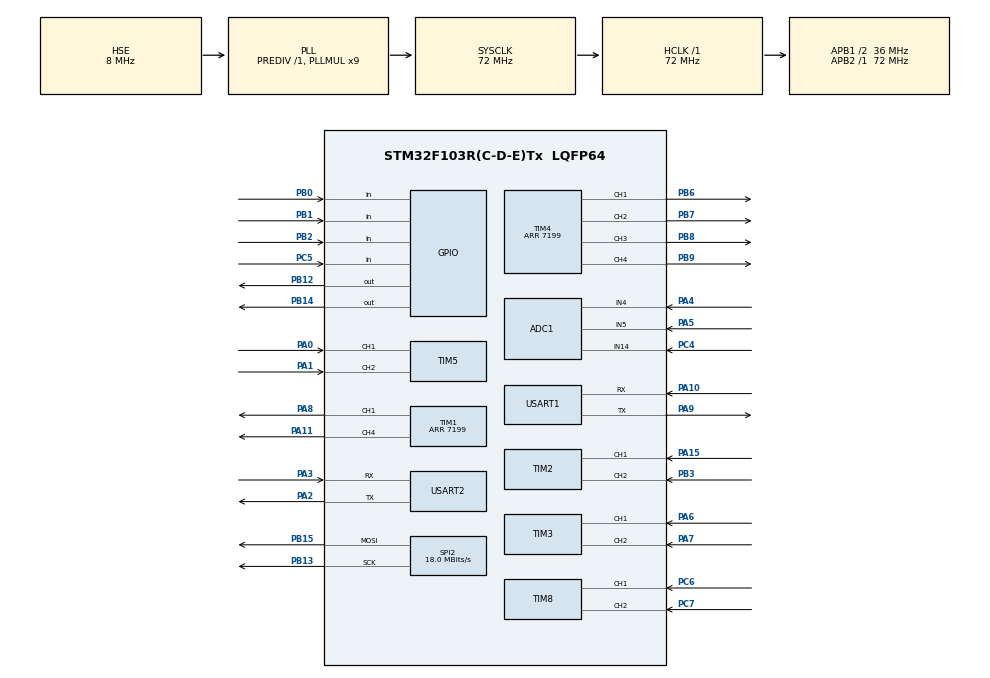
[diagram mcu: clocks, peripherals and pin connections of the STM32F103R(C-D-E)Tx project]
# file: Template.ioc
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ADC1.Channel-0\#ChannelRegularConversion=ADC_CHANNEL_4
ADC1.Channel-1\#ChannelRegularConversion=ADC_CHANNEL_5
ADC1.Channel-2\#ChannelRegularConversion=ADC_CHANNEL_14
ADC1.NbrOfConversion=3
ADC1.NbrOfConversionFlag=1
ADC1.Rank-0\#ChannelRegularConversion=1
ADC1.Rank-1\#ChannelRegularConversion=2
ADC1.Rank-2\#ChannelRegularConversion=3
ADC1.SamplingTime-0\#ChannelRegularConversion=ADC_SAMPLETIME_71CYCLES_5
ADC1.SamplingTime-1\#ChannelRegularConversion=ADC_SAMPLETIME_71CYCLES_5
ADC1.SamplingTime-2\#ChannelRegularConversion=ADC_SAMPLETIME_71CYCLES_5
ADC1.master=1
Dma.ADC1.3.Direction=DMA_PERIPH_TO_MEMORY
Dma.ADC1.3.Instance=DMA1_Channel1
Dma.ADC1.3.MemDataAlignment=DMA_MDATAALIGN_HALFWORD
Dma.ADC1.3.MemInc=DMA_MINC_ENABLE
Dma.ADC1.3.Mode=DMA_NORMAL
Dma.ADC1.3.PeriphDataAlignment=DMA_PDATAALIGN_HALFWORD
Dma.ADC1.3.PeriphInc=DMA_PINC_DISABLE
Dma.ADC1.3.Priority=DMA_PRIORITY_MEDIUM
Dma.Request0=USART2_RX
Dma.Request1=USART2_TX
Dma.Request2=SPI2_TX
Dma.Request3=ADC1
Dma.SPI2_TX.2.Direction=DMA_MEMORY_TO_PERIPH
Dma.SPI2_TX.2.Instance=DMA1_Channel5
Dma.SPI2_TX.2.MemDataAlignment=DMA_MDATAALIGN_BYTE
Dma.SPI2_TX.2.MemInc=DMA_MINC_ENABLE
Dma.SPI2_TX.2.Mode=DMA_NORMAL
Dma.SPI2_TX.2.PeriphDataAlignment=DMA_PDATAALIGN_BYTE
Dma.SPI2_TX.2.PeriphInc=DMA_PINC_DISABLE
Dma.SPI2_TX.2.Priority=DMA_PRIORITY_HIGH
Dma.USART2_RX.0.Direction=DMA_PERIPH_TO_MEMORY
Dma.USART2_RX.0.Instance=DMA1_Channel6
Dma.USART2_RX.0.MemDataAlignment=DMA_MDATAALIGN_BYTE
Dma.USART2_RX.0.MemInc=DMA_MINC_ENABLE
Dma.USART2_RX.0.Mode=DMA_CIRCULAR
Dma.USART2_RX.0.PeriphDataAlignment=DMA_PDATAALIGN_BYTE
Dma.USART2_RX.0.PeriphInc=DMA_PINC_DISABLE
Dma.USART2_RX.0.Priority=DMA_PRIORITY_LOW
Dma.USART2_TX.1.Direction=DMA_MEMORY_TO_PERIPH
Dma.USART2_TX.1.Instance=DMA1_Channel7
Dma.USART2_TX.1.MemDataAlignment=DMA_MDATAALIGN_BYTE
Dma.USART2_TX.1.MemInc=DMA_MINC_ENABLE
Dma.USART2_TX.1.Mode=DMA_NORMAL
Dma.USART2_TX.1.PeriphDataAlignment=DMA_PDATAALIGN_BYTE
Dma.USART2_TX.1.PeriphInc=DMA_PINC_DISABLE
Dma.USART2_TX.1.Priority=DMA_PRIORITY_LOW
Mcu.Family=STM32F1
Mcu.Name=STM32F103R(C-D-E)Tx
Mcu.Package=LQFP64
NVIC.DMA1_Channel1_IRQn=true\:5\:0\:true\:false\:true\:false\:true\:true
NVIC.DMA1_Channel5_IRQn=true\:5\:0\:true\:false\:true\:false\:true\:true
NVIC.DMA1_Channel6_IRQn=true\:5\:0\:true\:false\:true\:false\:true\:true
NVIC.DMA1_Channel7_IRQn=true\:5\:0\:true\:false\:true\:false\:true\:true
NVIC.PriorityGroup=NVIC_PRIORITYGROUP_4
NVIC.SPI2_IRQn=true\:7\:0\:true\:false\:true\:true\:true\:true
NVIC.TIM7_IRQn=true\:10\:0\:true\:false\:true\:true\:true\:true
NVIC.USART2_IRQn=true\:6\:0\:true\:false\:true\:true\:true\:true
PA0-WKUP.Signal=S_TIM5_CH1
PA1.Signal=S_TIM5_CH2
PA10.Mode=Asynchronous
PA10.Signal=USART1_RX
PA11.Signal=S_TIM1_CH4
PA13.Mode=Serial_Wire
PA13.Signal=SYS_JTMS-SWDIO
PA14.Mode=Serial_Wire
PA14.Signal=SYS_JTCK-SWCLK
PA15.Signal=S_TIM2_CH1_ETR
PA2.Mode=Asynchronous
PA2.Signal=USART2_TX
PA3.GPIO_PuPd=GPIO_PULLUP
PA3.Mode=Asynchronous
PA3.Signal=USART2_RX
PA4.Signal=ADCx_IN4
PA5.Signal=ADCx_IN5
PA6.Signal=S_TIM3_CH1
PA7.Signal=S_TIM3_CH2
PA8.Signal=S_TIM1_CH1
PA9.Mode=Asynchronous
PA9.Signal=USART1_TX
PB0.GPIO_PuPd=GPIO_PULLUP
PB0.Signal=GPIO_Input
PB1.GPIO_PuPd=GPIO_PULLUP
PB1.Signal=GPIO_Input
PB12.Signal=GPIO_Output
PB13.Mode=TX_Only_Simplex_Unidirect_Master
PB13.Signal=SPI2_SCK
PB14.Signal=GPIO_Output
PB15.Mode=TX_Only_Simplex_Unidirect_Master
PB15.Signal=SPI2_MOSI
PB2.GPIO_PuPd=GPIO_PULLUP
PB2.Signal=GPIO_Input
PB3.Signal=S_TIM2_CH2
PB6.Signal=S_TIM4_CH1
PB7.Signal=S_TIM4_CH2
PB8.Signal=S_TIM4_CH3
PB9.Signal=S_TIM4_CH4
PC4.Signal=ADCx_IN14
PC5.GPIO_PuPd=GPIO_PULLUP
PC5.Signal=GPIO_Input
PC6.Signal=S_TIM8_CH1
PC7.Signal=S_TIM8_CH2
PD0-OSC_IN.Mode=HSE-External-Oscillator
PD0-OSC_IN.Signal=RCC_OSC_IN
PD1-OSC_OUT.Mode=HSE-External-Oscillator
PD1-OSC_OUT.Signal=RCC_OSC_OUT
ProjectManager.HeapSize=0x200
ProjectManager.StackSize=0x400
ProjectManager.TargetToolchain=MDK-ARM V5.32
RCC.ADCPresc=RCC_ADCPCLK2_DIV6
RCC.AHBFreq_Value=72000000
RCC.APB1CLKDivider=RCC_HCLK_DIV2
RCC.APB1Freq_Value=36000000
RCC.APB1TimFreq_Value=72000000
RCC.APB2Freq_Value=72000000
RCC.APB2TimFreq_Value=72000000
RCC.HCLKFreq_Value=72000000
RCC.PLLMUL=RCC_PLL_MUL9
RCC.PLLSourceVirtual=RCC_PLLSOURCE_HSE
RCC.SYSCLKFreq_VALUE=72000000
RCC.SYSCLKSource=RCC_SYSCLKSOURCE_PLLCLK
RCC.USBFreq_Value=72000000
SH.ADCx_IN14.0=ADC1_IN14,IN14
SH.ADCx_IN4.0=ADC1_IN4,IN4
SH.ADCx_IN5.0=ADC1_IN5,IN5
SH.S_TIM1_CH1.0=TIM1_CH1,PWM Generation1 CH1
SH.S_TIM1_CH4.0=TIM1_CH4,PWM Generation4 CH4
SH.S_TIM2_CH1_ETR.0=TIM2_CH1,Encoder_Interface
SH.S_TIM2_CH2.0=TIM2_CH2,Encoder_Interface
SH.S_TIM3_CH1.0=TIM3_CH1,Encoder_Interface
SH.S_TIM3_CH2.0=TIM3_CH2,Encoder_Interface
SH.S_TIM4_CH1.0=TIM4_CH1,PWM Generation1 CH1
SH.S_TIM4_CH2.0=TIM4_CH2,PWM Generation2 CH2
SH.S_TIM4_CH3.0=TIM4_CH3,PWM Generation3 CH3
SH.S_TIM4_CH4.0=TIM4_CH4,PWM Generation4 CH4
SH.S_TIM5_CH1.0=TIM5_CH1,Encoder_Interface
SH.S_TIM5_CH2.0=TIM5_CH2,Encoder_Interface
SH.S_TIM8_CH1.0=TIM8_CH1,Encoder_Interface
SH.S_TIM8_CH2.0=TIM8_CH2,Encoder_Interface
SPI2.BaudRatePrescaler=SPI_BAUDRATEPRESCALER_2
SPI2.CLKPhase=SPI_PHASE_2EDGE
SPI2.CLKPolarity=SPI_POLARITY_HIGH
SPI2.CalculateBaudRate=18.0 MBits/s
SPI2.Direction=SPI_DIRECTION_2LINES
SPI2.Mode=SPI_MODE_MASTER
SPI2.VirtualType=VM_MASTER
TIM1.Channel-PWM\ Generation1\ CH1=TIM_CHANNEL_1
TIM1.Channel-PWM\ Generation4\ CH4=TIM_CHANNEL_4
TIM1.Period=7199
TIM2.EncoderMode=TIM_ENCODERMODE_TI1
TIM3.EncoderMode=TIM_ENCODERMODE_TI1
TIM4.Channel-PWM\ Generation1\ CH1=TIM_CHANNEL_1
TIM4.Channel-PWM\ Generation2\ CH2=TIM_CHANNEL_2
TIM4.Channel-PWM\ Generation3\ CH3=TIM_CHANNEL_3
TIM4.Channel-PWM\ Generation4\ CH4=TIM_CHANNEL_4
TIM4.Period=7199
TIM5.EncoderMode=TIM_ENCODERMODE_TI1
TIM7.AutoReloadPreload=TIM_AUTORELOAD_PRELOAD_ENABLE
TIM7.Period=99
TIM7.Prescaler=7199
TIM8.ClockDivision=TIM_CLOCKDIVISION_DIV2
TIM8.EncoderMode=TIM_ENCODERMODE_TI1
TIM8.IC1Filter=0xf
TIM8.IC1Prescaler=TIM_ICPSC_DIV1
TIM8.IC2Filter=0xf
TIM8.IC2Prescaler=TIM_ICPSC_DIV1
USART1.VirtualMode=VM_ASYNC
USART2.VirtualMode=VM_ASYNC
VP_TIM7_VS_ClockSourceINT.Mode=Enable_Timer
board=custom

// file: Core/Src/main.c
/* USER CODE BEGIN Header */
/**
  ******************************************************************************
  * @file           : main.c
  * @brief          : Main program body
  ******************************************************************************
  * @attention
  *
  * Copyright (c) 2025 STMicroelectronics.
  * All rights reserved.
  *
  * This software is licensed under terms that can be found in the LICENSE file
  * in the root directory of this software component.
  * If no LICENSE file comes with this software, it is provided AS-IS.
  *
  ******************************************************************************
  */
/* USER CODE END Header */
#include "main.h"
#include "adc.h"
#include "dma.h"
#include "spi.h"
#include "tim.h"
#include "usart.h"
#include "gpio.h"

/* USER CODE BEGIN Includes */
#include "OS/os.h"
/* USER CODE END Includes */

void SystemClock_Config(void);

int main(void)
{

  /* MCU Configuration--------------------------------------------------------*/

  /* Reset of all peripherals, Initializes the Flash interface and the Systick. */
  HAL_Init();

  /* Configure the system clock */
  SystemClock_Config();

  /* Initialize all configured peripherals */
  MX_GPIO_Init();
  MX_DMA_Init();
  MX_TIM7_Init();
  MX_USART1_UART_Init();
  MX_USART2_UART_Init();
  MX_TIM3_Init();
  MX_TIM4_Init();
  MX_SPI2_Init();
  MX_TIM2_Init();
  MX_ADC1_Init();
  MX_TIM5_Init();
  MX_TIM1_Init();
  MX_TIM8_Init();

  /* Infinite loop */
  /* USER CODE BEGIN WHILE */
	_os();
  while (1)
  {
    /* USER CODE END WHILE */

  }
}

void SystemClock_Config(void)
{
  RCC_OscInitTypeDef RCC_OscInitStruct = {0};
  RCC_ClkInitTypeDef RCC_ClkInitStruct = {0};
  RCC_PeriphCLKInitTypeDef PeriphClkInit = {0};

  /** Initializes the RCC Oscillators according to the specified parameters
  * in the RCC_OscInitTypeDef structure.
  */
  RCC_OscInitStruct.OscillatorType = RCC_OSCILLATORTYPE_HSE;
  RCC_OscInitStruct.HSEState = RCC_HSE_ON;
  RCC_OscInitStruct.HSEPredivValue = RCC_HSE_PREDIV_DIV1;
  RCC_OscInitStruct.HSIState = RCC_HSI_ON;
  RCC_OscInitStruct.PLL.PLLState = RCC_PLL_ON;
  RCC_OscInitStruct.PLL.PLLSource = RCC_PLLSOURCE_HSE;
  RCC_OscInitStruct.PLL.PLLMUL = RCC_PLL_MUL9;
  if (HAL_RCC_OscConfig(&RCC_OscInitStruct) != HAL_OK)
  {
    Error_Handler();
  }

  /** Initializes the CPU, AHB and APB buses clocks
  */
  RCC_ClkInitStruct.ClockType = RCC_CLOCKTYPE_HCLK|RCC_CLOCKTYPE_SYSCLK
                              |RCC_CLOCKTYPE_PCLK1|RCC_CLOCKTYPE_PCLK2;
  RCC_ClkInitStruct.SYSCLKSource = RCC_SYSCLKSOURCE_PLLCLK;
  RCC_ClkInitStruct.AHBCLKDivider = RCC_SYSCLK_DIV1;
  RCC_ClkInitStruct.APB1CLKDivider = RCC_HCLK_DIV2;
  RCC_ClkInitStruct.APB2CLKDivider = RCC_HCLK_DIV1;

  if (HAL_RCC_ClockConfig(&RCC_ClkInitStruct, FLASH_LATENCY_2) != HAL_OK)
  {
    Error_Handler();
  }
  PeriphClkInit.PeriphClockSelection = RCC_PERIPHCLK_ADC;
  PeriphClkInit.AdcClockSelection = RCC_ADCPCLK2_DIV6;
  if (HAL_RCCEx_PeriphCLKConfig(&PeriphClkInit) != HAL_OK)
  {
    Error_Handler();
  }
}

void Error_Handler(void)
{
  __disable_irq();
  while (1)
  {
  }
}
